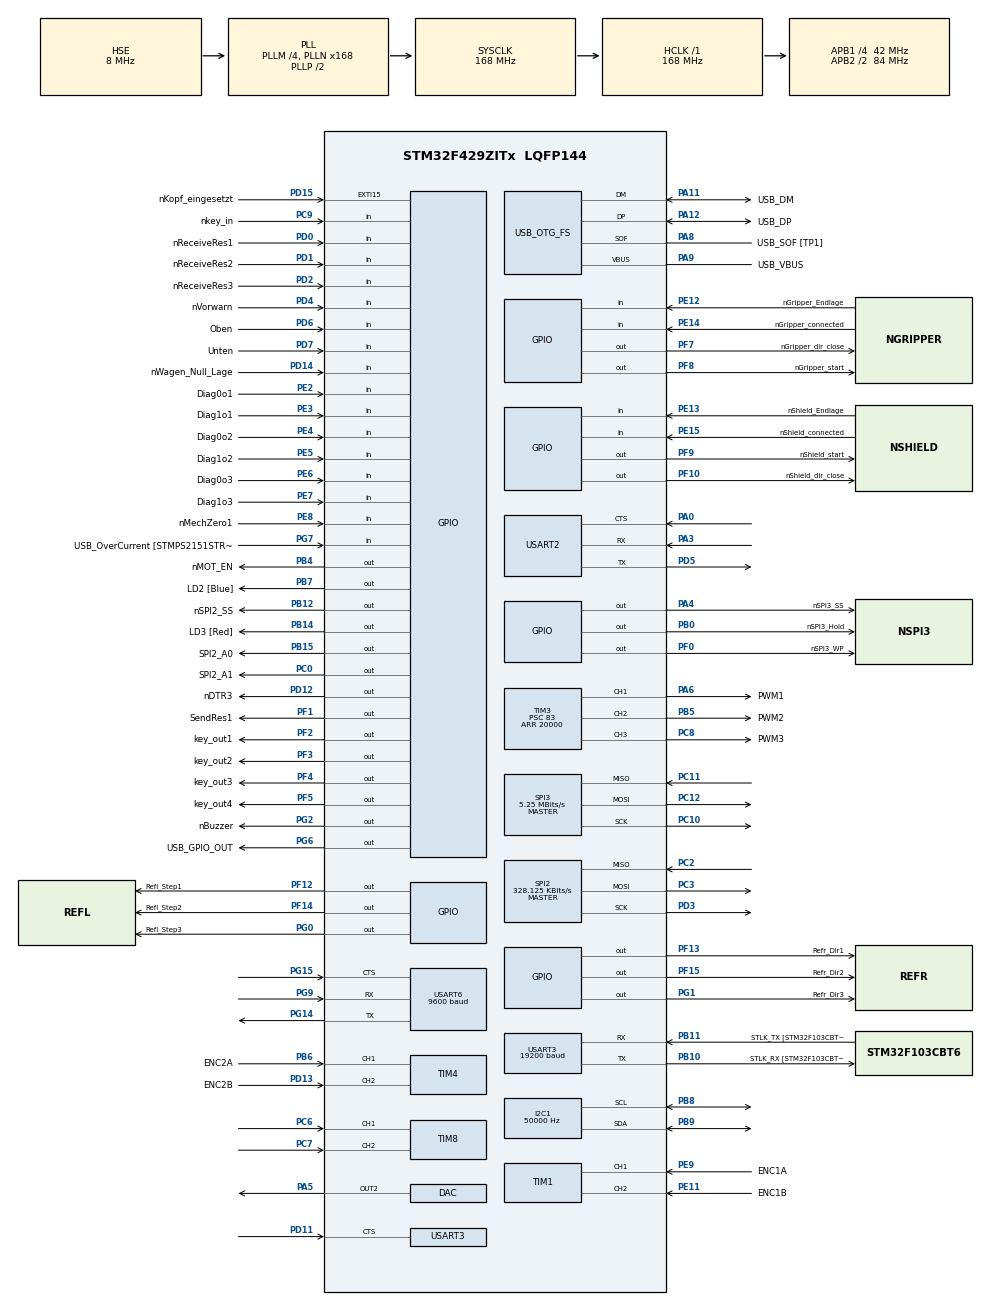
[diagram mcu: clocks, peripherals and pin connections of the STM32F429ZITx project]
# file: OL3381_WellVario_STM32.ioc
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I2C1.ClockSpeed=50000
IWDG.Prescaler=IWDG_PRESCALER_32
Mcu.Family=STM32F4
Mcu.Name=STM32F429ZITx
Mcu.Package=LQFP144
NVIC.EXTI15_10_IRQn=true\:1\:0\:true\:false\:true\:true\:true\:true
NVIC.PriorityGroup=NVIC_PRIORITYGROUP_4
NVIC.TIM1_BRK_TIM9_IRQn=true\:1\:0\:true\:false\:true\:true\:true\:true
NVIC.TIM1_CC_IRQn=true\:1\:0\:true\:false\:true\:true\:true\:true
NVIC.TIM1_TRG_COM_TIM11_IRQn=true\:1\:0\:true\:false\:true\:true\:true\:true
NVIC.TIM1_UP_TIM10_IRQn=true\:1\:0\:true\:false\:true\:true\:true\:true
NVIC.TIM3_IRQn=true\:1\:0\:true\:false\:true\:true\:true\:true
NVIC.TIM4_IRQn=true\:1\:0\:true\:false\:true\:true\:true\:true
NVIC.TIM8_BRK_TIM12_IRQn=true\:1\:0\:true\:false\:true\:true\:true\:true
NVIC.TIM8_CC_IRQn=true\:0\:0\:false\:false\:true\:true\:true\:true
NVIC.TIM8_TRG_COM_TIM14_IRQn=true\:1\:0\:true\:false\:true\:true\:true\:true
NVIC.TIM8_UP_TIM13_IRQn=true\:1\:0\:true\:false\:true\:true\:true\:true
NVIC.USART3_IRQn=true\:0\:0\:true\:false\:true\:true\:true\:true
PA0/WKUP.Mode=CTS_Only
PA0/WKUP.Signal=USART2_CTS
PA1.GPIO_Label=RMII_REF_CLK [LAN8742A-CZ-TR_REFCLK0]
PA1.Signal=ETH_REF_CLK
PA10.GPIO_Label=USB_ID
PA10.Signal=USB_OTG_FS_ID
PA11.GPIO_Label=USB_DM
PA11.Mode=Device_Only
PA11.Signal=USB_OTG_FS_DM
PA12.GPIO_Label=USB_DP
PA12.Mode=Device_Only
PA12.Signal=USB_OTG_FS_DP
PA13.GPIO_Label=TMS
PA13.Mode=Serial_Wire
PA13.Signal=SYS_JTMS-SWDIO
PA14.GPIO_Label=TCK
PA14.Mode=Serial_Wire
PA14.Signal=SYS_JTCK-SWCLK
PA2.GPIO_Label=RMII_MDIO [LAN8742A-CZ-TR_MDIO]
PA2.Signal=ETH_MDIO
PA3.Mode=Asynchronous
PA3.Signal=USART2_RX
PA4.GPIO_Label=nSPI3_SS
PA4.Signal=GPIO_Output
PA5.GPIO_Mode=GPIO_MODE_ANALOG
PA5.GPIO_PuPd=GPIO_NOPULL
PA5.Signal=COMP_DAC2_group
PA6.GPIO_Label=PWM1
PA6.Signal=S_TIM3_CH1
PA7.GPIO_Label=RMII_CRS_DV [LAN8742A-CZ-TR_CRS_DV]
PA7.Signal=ETH_CRS_DV
PA8.GPIO_Label=USB_SOF [TP1]
PA8.Mode=Activate_SOF_FS
PA8.Signal=USB_OTG_FS_SOF
PA9.GPIO_Label=USB_VBUS
PA9.Mode=Activate_VBUS
PA9.Signal=USB_OTG_FS_VBUS
PB0.GPIO_Label=nSPI3_Hold
PB0.PinState=GPIO_PIN_SET
PB0.Signal=GPIO_Output
PB10.GPIO_Label=STLK_RX [STM32F103CBT6_PA3]
PB10.Mode=Asynchronous
PB10.Signal=USART3_TX
PB11.GPIO_Label=STLK_TX [STM32F103CBT6_PA2]
PB11.Mode=Asynchronous
PB11.Signal=USART3_RX
PB12.GPIO_Label=nSPI2_SS
PB12.PinState=GPIO_PIN_SET
PB12.Signal=GPIO_Output
PB13.GPIO_Label=RMII_TXD1 [LAN8742A-CZ-TR_TXD1]
PB13.Signal=ETH_TXD1
PB14.GPIO_Label=LD3 [Red]
PB14.Signal=GPIO_Output
PB15.GPIO_Label=SPI2_A0
PB15.PinState=GPIO_PIN_SET
PB15.Signal=GPIO_Output
PB4.GPIO_Label=nMOT_EN
PB4.PinState=GPIO_PIN_SET
PB4.Signal=GPIO_Output
PB5.GPIO_Label=PWM2
PB5.Signal=S_TIM3_CH2
PB6.GPIO_Label=ENC2A
PB6.Signal=S_TIM4_CH1
PB7.GPIO_Label=LD2 [Blue]
PB7.Signal=GPIO_Output
PB8.Mode=I2C
PB8.Signal=I2C1_SCL
PB9.Mode=I2C
PB9.Signal=I2C1_SDA
PC0.GPIO_Label=SPI2_A1
PC0.PinState=GPIO_PIN_SET
PC0.Signal=GPIO_Output
PC1.GPIO_Label=RMII_MDC [LAN8742A-CZ-TR_MDC]
PC1.Signal=ETH_MDC
PC10.Mode=Full_Duplex_Master
PC10.Signal=SPI3_SCK
PC11.Mode=Full_Duplex_Master
PC11.Signal=SPI3_MISO
PC12.Mode=Full_Duplex_Master
PC12.Signal=SPI3_MOSI
PC14/OSC32_IN.Mode=LSE-External-Oscillator
PC14/OSC32_IN.Signal=RCC_OSC32_IN
PC15/OSC32_OUT.Mode=LSE-External-Oscillator
PC15/OSC32_OUT.Signal=RCC_OSC32_OUT
PC2.Mode=Full_Duplex_Master
PC2.Signal=SPI2_MISO
PC3.Mode=Full_Duplex_Master
PC3.Signal=SPI2_MOSI
PC4.GPIO_Label=RMII_RXD0 [LAN8742A-CZ-TR_RXD0]
PC4.Signal=ETH_RXD0
PC5.GPIO_Label=RMII_RXD1 [LAN8742A-CZ-TR_RXD1]
PC5.Signal=ETH_RXD1
PC6.Signal=S_TIM8_CH1
PC7.Signal=S_TIM8_CH2
PC8.GPIO_Label=PWM3
PC8.Signal=S_TIM3_CH3
PC9.GPIO_Label=nkey_in
PC9.GPIO_PuPd=GPIO_PULLUP
PC9.Signal=GPIO_Input
PD0.GPIO_Label=nReceiveRes1
PD0.Signal=GPIO_Input
PD1.GPIO_Label=nReceiveRes2
PD1.Signal=GPIO_Input
PD11.Mode=CTS_Only
PD11.Signal=USART3_CTS
PD12.GPIO_Label=nDTR3
PD12.PinState=GPIO_PIN_RESET
PD12.Signal=GPIO_Output
PD13.GPIO_Label=ENC2B
PD13.Signal=S_TIM4_CH2
PD14.GPIO_Label=nWagen_Null_Lage
PD14.Signal=GPIO_Input
PD15.GPIO_Label=nKopf_eingesetzt
PD15.GPIO_ModeDefaultEXTI=GPIO_MODE_IT_RISING_FALLING
PD15.GPIO_PuPd=GPIO_PULLUP
PD15.Signal=GPXTI15
PD2.GPIO_Label=nReceiveRes3
PD2.Signal=GPIO_Input
PD3.Mode=Full_Duplex_Master
PD3.Signal=SPI2_SCK
PD4.GPIO_Label=nVorwarn
PD4.Signal=GPIO_Input
PD5.GPIO_Speed=GPIO_SPEED_FREQ_VERY_HIGH
PD5.Mode=Asynchronous
PD5.Signal=USART2_TX
PD6.GPIO_Label=Oben
PD6.Signal=GPIO_Input
PD7.GPIO_Label=Unten
PD7.Signal=GPIO_Input
PE11.GPIO_Label=ENC1B
PE11.Signal=S_TIM1_CH2
PE12.GPIO_Label=nGripper_Endlage
PE12.Signal=GPIO_Input
PE13.GPIO_Label=nShield_Endlage
PE13.Signal=GPIO_Input
PE14.GPIO_Label=nGripper_connected
PE14.GPIO_PuPd=GPIO_PULLUP
PE14.Signal=GPIO_Input
PE15.GPIO_Label=nShield_connected
PE15.GPIO_PuPd=GPIO_PULLUP
PE15.Signal=GPIO_Input
PE2.GPIO_Label=Diag0o1
PE2.Signal=GPIO_Input
PE3.GPIO_Label=Diag1o1
PE3.Signal=GPIO_Input
PE4.GPIO_Label=Diag0o2
PE4.Signal=GPIO_Input
PE5.GPIO_Label=Diag1o2
PE5.Signal=GPIO_Input
PE6.GPIO_Label=Diag0o3
PE6.Signal=GPIO_Input
PE7.GPIO_Label=Diag1o3
PE7.Signal=GPIO_Input
PE8.GPIO_Label=nMechZero1
PE8.Signal=GPIO_Input
PE9.GPIO_Label=ENC1A
PE9.Signal=S_TIM1_CH1
PF0.GPIO_Label=nSPI3_WP
PF0.PinState=GPIO_PIN_SET
PF0.Signal=GPIO_Output
PF1.GPIO_Label=SendRes1
PF1.Signal=GPIO_Output
PF10.GPIO_Label=nShield_dir_close
PF10.PinState=GPIO_PIN_SET
PF10.Signal=GPIO_Output
PF12.GPIO_Label=Refl_Step1
PF12.Signal=GPIO_Output
PF13.GPIO_Label=Refr_Dir1
PF13.Signal=GPIO_Output
PF14.GPIO_Label=Refl_Step2
PF14.Signal=GPIO_Output
PF15.GPIO_Label=Refr_Dir2
PF15.Signal=GPIO_Output
PF2.GPIO_Label=key_out1
PF2.Signal=GPIO_Output
PF3.GPIO_Label=key_out2
PF3.Signal=GPIO_Output
PF4.GPIO_Label=key_out3
PF4.Signal=GPIO_Output
PF5.GPIO_Label=key_out4
PF5.Signal=GPIO_Output
PF7.GPIO_Label=nGripper_dir_close
PF7.PinState=GPIO_PIN_SET
PF7.Signal=GPIO_Output
PF8.GPIO_Label=nGripper_start
PF8.PinState=GPIO_PIN_SET
PF8.Signal=GPIO_Output
PF9.GPIO_Label=nShield_start
PF9.PinState=GPIO_PIN_SET
PF9.Signal=GPIO_Output
PG0.GPIO_Label=Refl_Step3
PG0.Signal=GPIO_Output
PG1.GPIO_Label=Refr_Dir3
PG1.Signal=GPIO_Output
PG11.GPIO_Label=RMII_TX_EN [LAN8742A-CZ-TR_TXEN]
PG11.Signal=ETH_TX_EN
PG13.GPIO_Label=RMII_TXD0 [LAN8742A-CZ-TR_TXD0]
PG13.Signal=ETH_TXD0
PG14.Mode=Asynchronous
PG14.Signal=USART6_TX
PG15.Mode=CTS_Only
PG15.Signal=USART6_CTS
PG2.GPIO_Label=nBuzzer
PG2.PinState=GPIO_PIN_SET
PG2.Signal=GPIO_Output
PG6.GPIO_Label=USB_GPIO_OUT
PG6.Signal=GPIO_Output
PG7.GPIO_Label=USB_OverCurrent [STMPS2151STR_FAULT]
PG7.Signal=GPIO_Input
PG9.Mode=Asynchronous
PG9.Signal=USART6_RX
PH0/OSC_IN.GPIO_Label=MCO [STM32F103CBT6_PA8]
PH0/OSC_IN.Mode=HSE-External-Oscillator
PH0/OSC_IN.Signal=RCC_OSC_IN
PH1/OSC_OUT.Mode=HSE-External-Oscillator
PH1/OSC_OUT.Signal=RCC_OSC_OUT
ProjectManager.HeapSize=0x200
ProjectManager.StackSize=0x400
ProjectManager.TargetToolchain=STM32CubeIDE
RCC.48MHZClocksFreq_Value=48000000
RCC.AHBFreq_Value=168000000
RCC.APB1CLKDivider=RCC_HCLK_DIV4
RCC.APB1Freq_Value=42000000
RCC.APB1TimFreq_Value=84000000
RCC.APB2CLKDivider=RCC_HCLK_DIV2
RCC.APB2Freq_Value=84000000
RCC.APB2TimFreq_Value=168000000
RCC.CortexFreq_Value=168000000
RCC.HCLKFreq_Value=168000000
RCC.HSE_VALUE=8000000
RCC.HSI_VALUE=16000000
RCC.PLLM=4
RCC.PLLMUL=RCC_PLL_MUL9
RCC.PLLN=168
RCC.PLLQ=7
RCC.PRESCALERUSB=RCC_USBCLKSOURCE_PLL_DIV1_5
RCC.SYSCLKFreq_VALUE=168000000
RCC.SYSCLKSource=RCC_SYSCLKSOURCE_PLLCLK
RCC.SYSCLKSourceVirtual=RCC_SYSCLKSOURCE_PLLCLK
RCC.USBFreq_Value=48000000
RCC.VCOOutputFreq_Value=336000000
SH.COMP_DAC2_group.0=DAC_OUT2,DAC_OUT2
SH.S_TIM1_CH1.0=TIM1_CH1,Encoder_Interface
SH.S_TIM1_CH2.0=TIM1_CH2,Encoder_Interface
SH.S_TIM3_CH1.0=TIM3_CH1,PWM Generation1 CH1
SH.S_TIM3_CH2.0=TIM3_CH2,PWM Generation2 CH2
SH.S_TIM3_CH3.0=TIM3_CH3,PWM Generation3 CH3
SH.S_TIM4_CH1.0=TIM4_CH1,Encoder_Interface
SH.S_TIM4_CH2.0=TIM4_CH2,Encoder_Interface
SH.S_TIM8_CH1.0=TIM8_CH1,Encoder_Interface
SH.S_TIM8_CH2.0=TIM8_CH2,Encoder_Interface
SPI2.BaudRatePrescaler=SPI_BAUDRATEPRESCALER_128
SPI2.CLKPhase=SPI_PHASE_2EDGE
SPI2.CLKPolarity=SPI_POLARITY_HIGH
SPI2.CalculateBaudRate=328.125 KBits/s
SPI2.Direction=SPI_DIRECTION_2LINES
SPI2.Mode=SPI_MODE_MASTER
SPI2.VirtualType=VM_MASTER
SPI3.BaudRatePrescaler=SPI_BAUDRATEPRESCALER_8
SPI3.CLKPhase=SPI_PHASE_2EDGE
SPI3.CLKPolarity=SPI_POLARITY_HIGH
SPI3.CalculateBaudRate=5.25 MBits/s
SPI3.Direction=SPI_DIRECTION_2LINES
SPI3.Mode=SPI_MODE_MASTER
SPI3.VirtualType=VM_MASTER
TIM1.EncoderMode=TIM_ENCODERMODE_TI12
TIM1.IC1Polarity=TIM_ICPOLARITY_FALLING
TIM1.IC2Polarity=TIM_ICPOLARITY_FALLING
TIM3.AutoReloadPreload=TIM_AUTORELOAD_PRELOAD_DISABLE
TIM3.Channel-PWM\ Generation1\ CH1=TIM_CHANNEL_1
TIM3.Channel-PWM\ Generation2\ CH2=TIM_CHANNEL_2
TIM3.Channel-PWM\ Generation3\ CH3=TIM_CHANNEL_3
TIM3.CounterMode=TIM_COUNTERMODE_UP
TIM3.OC1Preload_PWM=DISABLE
TIM3.OC2Preload_PWM=DISABLE
TIM3.OC3Preload_PWM=DISABLE
TIM3.OCFastMode_PWM-PWM\ Generation1\ CH1=TIM_OCFAST_DISABLE
TIM3.OCFastMode_PWM-PWM\ Generation2\ CH2=TIM_OCFAST_DISABLE
TIM3.OCFastMode_PWM-PWM\ Generation3\ CH3=TIM_OCFAST_DISABLE
TIM3.OCMode_PWM-PWM\ Generation2\ CH2=TIM_OCMODE_PWM1
TIM3.OCMode_PWM-PWM\ Generation3\ CH3=TIM_OCMODE_PWM1
TIM3.Period=20000
TIM3.Prescaler=83
TIM3.Pulse-PWM\ Generation1\ CH1=1000
TIM3.Pulse-PWM\ Generation2\ CH2=1500
TIM3.Pulse-PWM\ Generation3\ CH3=2000
TIM3.TIM_MasterOutputTrigger=TIM_TRGO_RESET
TIM4.EncoderMode=TIM_ENCODERMODE_TI12
TIM4.IC1Polarity=TIM_ICPOLARITY_FALLING
TIM4.IC2Polarity=TIM_ICPOLARITY_FALLING
TIM8.EncoderMode=TIM_ENCODERMODE_TI12
TIM8.IC1Polarity=TIM_ICPOLARITY_FALLING
TIM8.IC2Polarity=TIM_ICPOLARITY_FALLING
TIM8.RepetitionCounter=0
USART2.VirtualMode=VM_ASYNC
USART3.BaudRate=19200
USART3.Parity=PARITY_ODD
USART3.StopBits=STOPBITS_2
USART3.VirtualMode=VM_ASYNC
USART3.WordLength=WORDLENGTH_9B
USART6.BaudRate=9600
USART6.VirtualMode=VM_ASYNC
USB_OTG_FS.VirtualMode=Device_Only
VP_IWDG_VS_IWDG.Mode=IWDG_Activate
VP_TIM3_VS_ClockSourceINT.Mode=Internal
board=NUCLEO-F429ZI

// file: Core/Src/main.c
/* USER CODE BEGIN Header */
/**
  ******************************************************************************
  * @file           : main.c
  * @brief          : Main program body
  ******************************************************************************
  * @attention
  *
  * Copyright (c) 2022 STMicroelectronics.
  * All rights reserved.
  *
  * This software is licensed under terms that can be found in the LICENSE file
  * in the root directory of this software component.
  * If no LICENSE file comes with this software,it is provided AS-IS.
  *
  ******************************************************************************
  */
/* USER CODE END Header */
#include "main.h"

/* USER CODE BEGIN Includes */
#include <stdbool.h>							// define bool types
#include <stdio.h>								// for types in printf
#include <string.h>								// for types in printf
#include <math.h>								// für float

#include <main.h>
#include <MAIN_CYBI.h>							// ... define (old) type definitions

// ---------- BASE
#include <ig_define.h>
// ---------- Inc
#include <_encoder.h>
#include <_i2c_fram.h>
#include <_pwm_servo.h>
#include <_spi_eeprom.h>
#include <_tmc5130a.h>
#include <_uart_terminal.h>
// ---------- Master
#include <ch_ig_head.h>							// P2.8
#include <ch_ig_config.h>						// EEPROMReadDeviceType
// ---------- Pipettor_Allgemein/VolumenKorrektur
// ---------- Pipettor_Allgemein

/* USER CODE END Includes */

/* USER CODE BEGIN PTD */
const char HW_Revision[] ={"2.0"};
/* USER CODE END PTD */

DAC_HandleTypeDef hdac;

I2C_HandleTypeDef hi2c1;

IWDG_HandleTypeDef hiwdg;

SPI_HandleTypeDef hspi2;
SPI_HandleTypeDef hspi3;

TIM_HandleTypeDef htim1;
TIM_HandleTypeDef htim3;
TIM_HandleTypeDef htim4;
TIM_HandleTypeDef htim8;

UART_HandleTypeDef huart2;
UART_HandleTypeDef huart3;
UART_HandleTypeDef huart6;

PCD_HandleTypeDef hpcd_USB_OTG_FS;

/* USER CODE BEGIN PV */

uword g_uwWaitTime;
uword g_uwKeyRepeatTime;
uword g_uwBeepTime;
uword g_uwTimeout;
uword g_uwHeadSafetyTime;

//gloabl flags for polling
volatile int32_t global_flag_counter_10ms;
volatile int32_t global_counter_10ms;

bool _Diag0o1;
bool _Diag1o1;
bool _Diag0o2;
bool _Diag1o2;
bool _Diag0o3;
bool _Diag1o3;
bool _nReceiveRes1;
bool _nReceiveRes2;
bool _nReceiveRes3;
bool _nWagen_Null_Lage;
bool _nVorwarn;
bool _Oben;
bool _Unten;
bool _nKopf_eingesetzt;
bool _nMechZero1;
bool _nGripper_connected;
bool _nShield_connected;
bool _nGripper_Endlage;
bool _nShield_Endlage;

/* USER CODE END PV */

void SystemClock_Config(void);
static void MX_GPIO_Init(void);
static void MX_USART3_UART_Init(void);
static void MX_USB_OTG_FS_PCD_Init(void);
static void MX_TIM4_Init(void);
static void MX_TIM3_Init(void);
static void MX_TIM8_Init(void);
static void MX_TIM1_Init(void);
static void MX_I2C1_Init(void);
static void MX_USART2_UART_Init(void);
static void MX_USART6_UART_Init(void);
static void MX_SPI2_Init(void);
static void MX_SPI3_Init(void);
static void MX_DAC_Init(void);
static void MX_IWDG_Init(void);
/* USER CODE BEGIN PFP */

// encoder (old Timer - Register replacement)
extern volatile int16_t HrzEncoder;					// Enc.1 (was T2) replacements for old (C167CS) hardware registers
extern volatile int16_t VertEncoder;				// Enc.2 (was T3)
volatile int16_t 		T4Encoder; 					// Enc.3 (Was T4) nur bei Drehtisch (Disk) angeschlossen,initialisiert,aber nicht genutzt

// ----- tick, Timer, Watchdog
void HAL_IncTick(void)
{								// cycle: 10 ms
	uwTick += uwTickFreq;							// original system function
}

void TimeCounters10ms(void)
{
	if(g_uwTimeout > 0) g_uwTimeout--;
	if(g_uwWaitTime > 0) g_uwWaitTime--;
	if(g_uwBeepTime > 0) g_uwBeepTime--;
	if(g_uwKeyRepeatTime > 0) g_uwKeyRepeatTime--;
}

void SetWaitTime(unsigned short usValue)
{
	g_uwWaitTime = usValue;
}

unsigned short IsWaitTime(void)
{
	return g_uwWaitTime;
}

void ResetWaitTime(void)
{
	g_uwWaitTime = 0;
}

void WDO(void)
{
	HAL_IWDG_Refresh(&hiwdg);						// timeout: 4 s
}

// keyboard
void KeySetRequest(uint16_t KeyNumber)
{
	HAL_GPIO_WritePin(key_out1_GPIO_Port,key_out1_Pin,(KeyNumber & 1));
	HAL_GPIO_WritePin(key_out2_GPIO_Port,key_out2_Pin,(KeyNumber & 2));
	HAL_GPIO_WritePin(key_out3_GPIO_Port,key_out3_Pin,(KeyNumber & 4));
	HAL_GPIO_WritePin(key_out4_GPIO_Port,key_out4_Pin,(KeyNumber & 8));
}
/* USER CODE END PFP */

int main(void)
{

	/* MCU Configuration--------------------------------------------------------*/

	/* Reset of all peripherals, Initializes the Flash interface and the Systick. */
	HAL_Init();

	/* Configure the system clock */
	SystemClock_Config();

	/* Initialize all configured peripherals */
	MX_GPIO_Init();
	MX_USART3_UART_Init();
	MX_USB_OTG_FS_PCD_Init();
	MX_TIM4_Init();
	MX_TIM3_Init();
	MX_TIM8_Init();
	MX_TIM1_Init();
	MX_I2C1_Init();
	MX_USART2_UART_Init();
	MX_USART6_UART_Init();
	MX_SPI2_Init();
	MX_SPI3_Init();
	MX_DAC_Init();
	MX_IWDG_Init();

	//while(HAL_SetTickFreq(HAL_TICK_FREQ_100HZ) != HAL_OK)	WDO();	// init 10 ms Tick
	while(HAL_SetTickFreq(HAL_TICK_FREQ_1KHZ) != HAL_OK)	WDO();	// init  1 ms Tick

	// ----- keyboard
	KeySetRequest(0);		// set Decoder Address to key1

	// ----- Gripper,Shield -----
	Gripper_Stop;
	Gripper_Open;
	Shield_Stop;
	Shield_Open_VcStop;

	// ----- read io state
	for (int i=0; i<5;i++)
	{
		_Diag0o1 = Diag0o1_RD;							//Poll			(reserviert Motorsteuerung)
		_Diag1o1 = Diag1o1_RD;							//Poll		H
		_Diag0o2 = Diag0o2_RD;							//Poll
		_Diag1o2 = Diag1o2_RD;							//Poll		H
		_Diag0o3 = Diag0o3_RD;							//Poll
		_Diag1o3 = Diag1o3_RD;							//Poll		H

		_nReceiveRes1 = nReceiveRes1_RD;				//ExtI0		L	P5_0	DiskFineZero						(ENC1_N Drehtisch_485 - nur bei "Disk" aktiv)
		_nReceiveRes2 = nReceiveRes2_RD;				//ExtI1			P5_4										(ENC2_N Ausheber)
		_nReceiveRes3 = nReceiveRes3_RD;				//ExtI2			P5_8	!DiskRawZeroRequest					(ENC3_N Drehtisch_485 - nur Grobnull)

		_nVorwarn = nVorwarn_RD;						//ExtI4			IN0[1]	VertReadAdvancePos					(Ausheber)
		_Oben = Oben_RD;								//ExtI6		H	IN0[4]	unused								(Ausheber)
		_Unten = Unten_RD;								//ExtI7			IN0[0]	VertReadEndPos						(Ausheber)

		_nKopf_eingesetzt = nKopf_eingesetzt_RD;		//ExtI15	L	P2_8	pos_edge -> UnexpectedHeadRemove()	(XS19/2, mit XS6 verbunden)
		_nMechZero1 = nMechZero1_RD;					//ExtI8		L	P5_2	HeadConnectionPin; PullUp			(XS6, mit XS19/2 verbunden)

		//	nMechZero2 = HIGH;							//Closed		P5_6	IsHeadShieldOpen / JALOUSIE_OPEN	S4 - Abdeckung

		//	nMechZero3 = HIGH;							//Closed		P5_10	HrzZeroRequest3714					S2 - Kopfhaube

		_nWagen_Null_Lage = nWagen_Null_Lage_RD;		//ExtI14				HrzZeroRequestStd					(Wagen)

		//	IsHeadShieldOpen: (IN2[2]==0) (S4 Jalousie bis V1.20), (IN2[3]==0) (S4 Jalousie ab V1.21), (P5_6==0) (S4 Überwachung Abdeckung)

		_nGripper_connected = nGripper_connected_RD;	//Poll			(Parkzange)
		_nGripper_Endlage = nGripper_Endlage_RD;		//ExtI12

		_nShield_connected = nShield_connected_RD;		//Poll			(Schutzschild)
		_nShield_Endlage = nShield_Endlage_RD;			//ExtI13

		HAL_Delay(10);
		WDO();
	}

	// ----- PWM
	PWM_init();			// Stop_all,0° = 1520ms

	// ----- DAC ----- (Ain_Iref)
	HAL_DAC_Start(&hdac,DAC_CHANNEL_2);
	HAL_DAC_SetValue(&hdac,DAC_CHANNEL_2,DAC_ALIGN_12B_R,0x07FF);	// 50% = around 2V35 @ TMC,reserved / not used now

	// ----- Encoder -----
	SendRes1_H;			// no index puls
	ENCODER_start();	// start Encoder Counter
	// replacements for old (C167CS) hardware registers:
	HrzEncoder = 0;		// Enc.1 (was T2) Hrz / Tisch
	VertEncoder = 0;	// Enc.2 (was T3) Vert / Ausheber
	T4Encoder = 0; 		// Enc.3 (Was T4) Disk / Drehtisch - initialisiert, aber ungenutzt

	// ----- nucleo
	LD1_ON;				// Green (EEPROM nSPI3_Hold = not holding)
	LD2_ON;				// Blue
	LD3_ON;				// Red
	HAL_Delay(100);
	LD1_OFF;			// Green (EEPROM nSPI3_Hold)
	LD2_OFF;			// Blue
	LD3_OFF;			// Red
	WDO();

	// ----- Steppers -----
	HAL_Delay(900);	// wait of end TMC5130 Controllers boot-sequence
	WDO();

	MOT_EN_ON;
	SPI2_A0_H;			// address 4 -> dummy unit
	SPI2_A1_H;
	nSPI2_SS_H;			// not selected

	tmc5130a_init();	// Set Motor Preferences
	HAL_Delay(100);
	WDO();

	float varrpm = 0.2;												// Test mit Fließkommazahl
	tmc5130a_VELOCITY(0, (uint32_t) (varrpm	*M1_SpU	*uSpS /60));	// Pumpe
	tmc5130a_VELOCITY(1, (uint32_t) (varrpm	*M2_SpU	*uSpS /60));	// Ausheber
	tmc5130a_VELOCITY(2, (uint32_t) (varrpm	*M3_SpU	*uSpS /60));	// Drehtisch

	// ----- Buzzer -----
	Buzzer_Beep(50);

	// ----- uart -----
	DTR3_ON;
	UART3_Start();
	setvbuf(stdout, NULL, _IONBF, 0); //Send strings without nullterminator
	setvbuf( stdin, NULL, _IONBF, 0); //get single chars

	/* Infinite loop */
	while (1)
	{
		WDO();
		main_cybi();					// start / run original maschine
	}

}

void SystemClock_Config(void)
{
	RCC_OscInitTypeDef RCC_OscInitStruct = {0};
	RCC_ClkInitTypeDef RCC_ClkInitStruct = {0};

	/** Configure the main internal regulator output voltage
	*/
	__HAL_RCC_PWR_CLK_ENABLE();
	__HAL_PWR_VOLTAGESCALING_CONFIG(PWR_REGULATOR_VOLTAGE_SCALE1);

	/** Initializes the RCC Oscillators according to the specified parameters
	* in the RCC_OscInitTypeDef structure.
	*/
	RCC_OscInitStruct.OscillatorType = RCC_OSCILLATORTYPE_LSI|RCC_OSCILLATORTYPE_HSE;
	RCC_OscInitStruct.HSEState = RCC_HSE_ON;
	RCC_OscInitStruct.LSIState = RCC_LSI_ON;
	RCC_OscInitStruct.PLL.PLLState = RCC_PLL_ON;
	RCC_OscInitStruct.PLL.PLLSource = RCC_PLLSOURCE_HSE;
	RCC_OscInitStruct.PLL.PLLM = 4;
	RCC_OscInitStruct.PLL.PLLN = 168;
	RCC_OscInitStruct.PLL.PLLP = RCC_PLLP_DIV2;
	RCC_OscInitStruct.PLL.PLLQ = 7;
	if (HAL_RCC_OscConfig(&RCC_OscInitStruct) != HAL_OK)
	{
		Error_Handler();
	}

	/** Initializes the CPU, AHB and APB buses clocks
	*/
	RCC_ClkInitStruct.ClockType = RCC_CLOCKTYPE_HCLK|RCC_CLOCKTYPE_SYSCLK
							  |RCC_CLOCKTYPE_PCLK1|RCC_CLOCKTYPE_PCLK2;
	RCC_ClkInitStruct.SYSCLKSource = RCC_SYSCLKSOURCE_PLLCLK;
	RCC_ClkInitStruct.AHBCLKDivider = RCC_SYSCLK_DIV1;
	RCC_ClkInitStruct.APB1CLKDivider = RCC_HCLK_DIV4;
	RCC_ClkInitStruct.APB2CLKDivider = RCC_HCLK_DIV2;

	if (HAL_RCC_ClockConfig(&RCC_ClkInitStruct, FLASH_LATENCY_5) != HAL_OK)
	{
		Error_Handler();
	}
}

static void MX_DAC_Init(void)
{

	DAC_ChannelConfTypeDef sConfig = {0};

	/** DAC Initialization
	*/
	hdac.Instance = DAC;
	if (HAL_DAC_Init(&hdac) != HAL_OK)
	{
		Error_Handler();
	}

	/** DAC channel OUT2 config
	*/
	sConfig.DAC_Trigger = DAC_TRIGGER_NONE;
	sConfig.DAC_OutputBuffer = DAC_OUTPUTBUFFER_ENABLE;
	if (HAL_DAC_ConfigChannel(&hdac, &sConfig, DAC_CHANNEL_2) != HAL_OK)
	{
		Error_Handler();
	}
}

static void MX_I2C1_Init(void)
{

	hi2c1.Instance = I2C1;
	hi2c1.Init.ClockSpeed = 50000;
	hi2c1.Init.DutyCycle = I2C_DUTYCYCLE_2;
	hi2c1.Init.OwnAddress1 = 0;
	hi2c1.Init.AddressingMode = I2C_ADDRESSINGMODE_7BIT;
	hi2c1.Init.DualAddressMode = I2C_DUALADDRESS_DISABLE;
	hi2c1.Init.OwnAddress2 = 0;
	hi2c1.Init.GeneralCallMode = I2C_GENERALCALL_DISABLE;
	hi2c1.Init.NoStretchMode = I2C_NOSTRETCH_DISABLE;
	if (HAL_I2C_Init(&hi2c1) != HAL_OK)
	{
		Error_Handler();
	}

	/** Configure Analogue filter
	*/
	if (HAL_I2CEx_ConfigAnalogFilter(&hi2c1, I2C_ANALOGFILTER_ENABLE) != HAL_OK)
	{
		Error_Handler();
	}

	/** Configure Digital filter
	*/
	if (HAL_I2CEx_ConfigDigitalFilter(&hi2c1, 0) != HAL_OK)
	{
		Error_Handler();
	}

}

static void MX_IWDG_Init(void)
{

	hiwdg.Instance = IWDG;
	hiwdg.Init.Prescaler = IWDG_PRESCALER_32;
	hiwdg.Init.Reload = 4095;
	if (HAL_IWDG_Init(&hiwdg) != HAL_OK)
	{
		Error_Handler();
	}

}

static void MX_SPI2_Init(void)
{

	/* SPI2 parameter configuration*/
	hspi2.Instance = SPI2;
	hspi2.Init.Mode = SPI_MODE_MASTER;
	hspi2.Init.Direction = SPI_DIRECTION_2LINES;
	hspi2.Init.DataSize = SPI_DATASIZE_8BIT;
	hspi2.Init.CLKPolarity = SPI_POLARITY_HIGH;
	hspi2.Init.CLKPhase = SPI_PHASE_2EDGE;
	hspi2.Init.NSS = SPI_NSS_SOFT;
	hspi2.Init.BaudRatePrescaler = SPI_BAUDRATEPRESCALER_128;
	hspi2.Init.FirstBit = SPI_FIRSTBIT_MSB;
	hspi2.Init.TIMode = SPI_TIMODE_DISABLE;
	hspi2.Init.CRCCalculation = SPI_CRCCALCULATION_DISABLE;
	hspi2.Init.CRCPolynomial = 10;
	if (HAL_SPI_Init(&hspi2) != HAL_OK)
	{
		Error_Handler();
	}

}

static void MX_SPI3_Init(void)
{

	/* SPI3 parameter configuration*/
	hspi3.Instance = SPI3;
	hspi3.Init.Mode = SPI_MODE_MASTER;
	hspi3.Init.Direction = SPI_DIRECTION_2LINES;
	hspi3.Init.DataSize = SPI_DATASIZE_8BIT;
	hspi3.Init.CLKPolarity = SPI_POLARITY_HIGH;
	hspi3.Init.CLKPhase = SPI_PHASE_2EDGE;
	hspi3.Init.NSS = SPI_NSS_SOFT;
	hspi3.Init.BaudRatePrescaler = SPI_BAUDRATEPRESCALER_8;
	hspi3.Init.FirstBit = SPI_FIRSTBIT_MSB;
	hspi3.Init.TIMode = SPI_TIMODE_DISABLE;
	hspi3.Init.CRCCalculation = SPI_CRCCALCULATION_DISABLE;
	hspi3.Init.CRCPolynomial = 10;
	if (HAL_SPI_Init(&hspi3) != HAL_OK)
	{
		Error_Handler();
	}

}

static void MX_TIM1_Init(void)
{

	TIM_Encoder_InitTypeDef sConfig = {0};
	TIM_MasterConfigTypeDef sMasterConfig = {0};

	htim1.Instance = TIM1;
	htim1.Init.Prescaler = 0;
	htim1.Init.CounterMode = TIM_COUNTERMODE_UP;
	htim1.Init.Period = 65535;
	htim1.Init.ClockDivision = TIM_CLOCKDIVISION_DIV1;
	htim1.Init.RepetitionCounter = 0;
	htim1.Init.AutoReloadPreload = TIM_AUTORELOAD_PRELOAD_DISABLE;
	sConfig.EncoderMode = TIM_ENCODERMODE_TI12;
	sConfig.IC1Polarity = TIM_ICPOLARITY_FALLING;
	sConfig.IC1Selection = TIM_ICSELECTION_DIRECTTI;
	sConfig.IC1Prescaler = TIM_ICPSC_DIV1;
	sConfig.IC1Filter = 0;
	sConfig.IC2Polarity = TIM_ICPOLARITY_FALLING;
	sConfig.IC2Selection = TIM_ICSELECTION_DIRECTTI;
	sConfig.IC2Prescaler = TIM_ICPSC_DIV1;
	sConfig.IC2Filter = 0;
	if (HAL_TIM_Encoder_Init(&htim1, &sConfig) != HAL_OK)
	{
		Error_Handler();
	}
	sMasterConfig.MasterOutputTrigger = TIM_TRGO_RESET;
	sMasterConfig.MasterSlaveMode = TIM_MASTERSLAVEMODE_DISABLE;
	if (HAL_TIMEx_MasterConfigSynchronization(&htim1, &sMasterConfig) != HAL_OK)
	{
		Error_Handler();
	}
}

static void MX_TIM3_Init(void)
{

	TIM_ClockConfigTypeDef sClockSourceConfig = {0};
	TIM_MasterConfigTypeDef sMasterConfig = {0};
	TIM_OC_InitTypeDef sConfigOC = {0};

	htim3.Instance = TIM3;
	htim3.Init.Prescaler = 83;
	htim3.Init.CounterMode = TIM_COUNTERMODE_UP;
	htim3.Init.Period = 20000;
	htim3.Init.ClockDivision = TIM_CLOCKDIVISION_DIV1;
	htim3.Init.AutoReloadPreload = TIM_AUTORELOAD_PRELOAD_DISABLE;
	if (HAL_TIM_Base_Init(&htim3) != HAL_OK)
	{
		Error_Handler();
	}
	sClockSourceConfig.ClockSource = TIM_CLOCKSOURCE_INTERNAL;
	if (HAL_TIM_ConfigClockSource(&htim3, &sClockSourceConfig) != HAL_OK)
	{
		Error_Handler();
	}
	if (HAL_TIM_PWM_Init(&htim3) != HAL_OK)
	{
		Error_Handler();
	}
	sMasterConfig.MasterOutputTrigger = TIM_TRGO_RESET;
	sMasterConfig.MasterSlaveMode = TIM_MASTERSLAVEMODE_DISABLE;
	if (HAL_TIMEx_MasterConfigSynchronization(&htim3, &sMasterConfig) != HAL_OK)
	{
		Error_Handler();
	}
	sConfigOC.OCMode = TIM_OCMODE_PWM1;
	sConfigOC.Pulse = 1000;
	sConfigOC.OCPolarity = TIM_OCPOLARITY_HIGH;
	sConfigOC.OCFastMode = TIM_OCFAST_DISABLE;
	if (HAL_TIM_PWM_ConfigChannel(&htim3, &sConfigOC, TIM_CHANNEL_1) != HAL_OK)
	{
		Error_Handler();
	}
	__HAL_TIM_DISABLE_OCxPRELOAD(&htim3, TIM_CHANNEL_1);
	sConfigOC.Pulse = 1500;
	if (HAL_TIM_PWM_ConfigChannel(&htim3, &sConfigOC, TIM_CHANNEL_2) != HAL_OK)
	{
		Error_Handler();
	}
	__HAL_TIM_DISABLE_OCxPRELOAD(&htim3, TIM_CHANNEL_2);
	sConfigOC.Pulse = 2000;
	if (HAL_TIM_PWM_ConfigChannel(&htim3, &sConfigOC, TIM_CHANNEL_3) != HAL_OK)
	{
		Error_Handler();
	}
	__HAL_TIM_DISABLE_OCxPRELOAD(&htim3, TIM_CHANNEL_3);
	HAL_TIM_MspPostInit(&htim3);

}

static void MX_TIM4_Init(void)
{

	TIM_Encoder_InitTypeDef sConfig = {0};
	TIM_MasterConfigTypeDef sMasterConfig = {0};

	htim4.Instance = TIM4;
	htim4.Init.Prescaler = 0;
	htim4.Init.CounterMode = TIM_COUNTERMODE_UP;
	htim4.Init.Period = 65535;
	htim4.Init.ClockDivision = TIM_CLOCKDIVISION_DIV1;
	htim4.Init.AutoReloadPreload = TIM_AUTORELOAD_PRELOAD_DISABLE;
	sConfig.EncoderMode = TIM_ENCODERMODE_TI12;
	sConfig.IC1Polarity = TIM_ICPOLARITY_FALLING;
	sConfig.IC1Selection = TIM_ICSELECTION_DIRECTTI;
	sConfig.IC1Prescaler = TIM_ICPSC_DIV1;
	sConfig.IC1Filter = 0;
	sConfig.IC2Polarity = TIM_ICPOLARITY_FALLING;
	sConfig.IC2Selection = TIM_ICSELECTION_DIRECTTI;
	sConfig.IC2Prescaler = TIM_ICPSC_DIV1;
	sConfig.IC2Filter = 0;
	if (HAL_TIM_Encoder_Init(&htim4, &sConfig) != HAL_OK)
	{
		Error_Handler();
	}
	sMasterConfig.MasterOutputTrigger = TIM_TRGO_RESET;
	sMasterConfig.MasterSlaveMode = TIM_MASTERSLAVEMODE_DISABLE;
	if (HAL_TIMEx_MasterConfigSynchronization(&htim4, &sMasterConfig) != HAL_OK)
	{
		Error_Handler();
	}

}

static void MX_TIM8_Init(void)
{

	TIM_Encoder_InitTypeDef sConfig = {0};
	TIM_MasterConfigTypeDef sMasterConfig = {0};

	htim8.Instance = TIM8;
	htim8.Init.Prescaler = 0;
	htim8.Init.CounterMode = TIM_COUNTERMODE_UP;
	htim8.Init.Period = 65535;
	htim8.Init.ClockDivision = TIM_CLOCKDIVISION_DIV1;
	htim8.Init.RepetitionCounter = 0;
	htim8.Init.AutoReloadPreload = TIM_AUTORELOAD_PRELOAD_DISABLE;
	sConfig.EncoderMode = TIM_ENCODERMODE_TI12;
	sConfig.IC1Polarity = TIM_ICPOLARITY_FALLING;
	sConfig.IC1Selection = TIM_ICSELECTION_DIRECTTI;
	sConfig.IC1Prescaler = TIM_ICPSC_DIV1;
	sConfig.IC1Filter = 0;
	sConfig.IC2Polarity = TIM_ICPOLARITY_FALLING;
	sConfig.IC2Selection = TIM_ICSELECTION_DIRECTTI;
	sConfig.IC2Prescaler = TIM_ICPSC_DIV1;
	sConfig.IC2Filter = 0;
	if (HAL_TIM_Encoder_Init(&htim8, &sConfig) != HAL_OK)
	{
		Error_Handler();
	}
	sMasterConfig.MasterOutputTrigger = TIM_TRGO_RESET;
	sMasterConfig.MasterSlaveMode = TIM_MASTERSLAVEMODE_DISABLE;
	if (HAL_TIMEx_MasterConfigSynchronization(&htim8, &sMasterConfig) != HAL_OK)
	{
		Error_Handler();
	}

}

static void MX_USART2_UART_Init(void)
{

	huart2.Instance = USART2;
	huart2.Init.BaudRate = 115200;
	huart2.Init.WordLength = UART_WORDLENGTH_8B;
	huart2.Init.StopBits = UART_STOPBITS_1;
	huart2.Init.Parity = UART_PARITY_NONE;
	huart2.Init.Mode = UART_MODE_TX_RX;
	huart2.Init.HwFlowCtl = UART_HWCONTROL_CTS;
	huart2.Init.OverSampling = UART_OVERSAMPLING_16;
	if (HAL_UART_Init(&huart2) != HAL_OK)
	{
		Error_Handler();
	}

}

static void MX_USART3_UART_Init(void)
{

	huart3.Instance = USART3;
	huart3.Init.BaudRate = 19200;
	huart3.Init.WordLength = UART_WORDLENGTH_9B;
	huart3.Init.StopBits = UART_STOPBITS_2;
	huart3.Init.Parity = UART_PARITY_ODD;
	huart3.Init.Mode = UART_MODE_TX_RX;
	huart3.Init.HwFlowCtl = UART_HWCONTROL_NONE;
	huart3.Init.OverSampling = UART_OVERSAMPLING_16;
	if (HAL_UART_Init(&huart3) != HAL_OK)
	{
		Error_Handler();
	}

}

static void MX_USART6_UART_Init(void)
{

	huart6.Instance = USART6;
	huart6.Init.BaudRate = 9600;
	huart6.Init.WordLength = UART_WORDLENGTH_8B;
	huart6.Init.StopBits = UART_STOPBITS_1;
	huart6.Init.Parity = UART_PARITY_NONE;
	huart6.Init.Mode = UART_MODE_TX_RX;
	huart6.Init.HwFlowCtl = UART_HWCONTROL_NONE;
	huart6.Init.OverSampling = UART_OVERSAMPLING_16;
	if (HAL_UART_Init(&huart6) != HAL_OK)
	{
		Error_Handler();
	}

}

static void MX_USB_OTG_FS_PCD_Init(void)
{

	hpcd_USB_OTG_FS.Instance = USB_OTG_FS;
	hpcd_USB_OTG_FS.Init.dev_endpoints = 4;
	hpcd_USB_OTG_FS.Init.speed = PCD_SPEED_FULL;
	hpcd_USB_OTG_FS.Init.dma_enable = DISABLE;
	hpcd_USB_OTG_FS.Init.phy_itface = PCD_PHY_EMBEDDED;
	hpcd_USB_OTG_FS.Init.Sof_enable = ENABLE;
	hpcd_USB_OTG_FS.Init.low_power_enable = DISABLE;
	hpcd_USB_OTG_FS.Init.lpm_enable = DISABLE;
	hpcd_USB_OTG_FS.Init.vbus_sensing_enable = ENABLE;
	hpcd_USB_OTG_FS.Init.use_dedicated_ep1 = DISABLE;
	if (HAL_PCD_Init(&hpcd_USB_OTG_FS) != HAL_OK)
	{
		Error_Handler();
	}

}

static void MX_GPIO_Init(void)
{
	GPIO_InitTypeDef GPIO_InitStruct = {0};

	/* GPIO Ports Clock Enable */
	__HAL_RCC_GPIOE_CLK_ENABLE();
	__HAL_RCC_GPIOC_CLK_ENABLE();
	__HAL_RCC_GPIOF_CLK_ENABLE();
	__HAL_RCC_GPIOH_CLK_ENABLE();
	__HAL_RCC_GPIOA_CLK_ENABLE();
	__HAL_RCC_GPIOB_CLK_ENABLE();
	__HAL_RCC_GPIOG_CLK_ENABLE();
	__HAL_RCC_GPIOD_CLK_ENABLE();

	/*Configure GPIO pin Output Level */
	HAL_GPIO_WritePin(GPIOF, nSPI3_WP_Pin|nGripper_dir_close_Pin|nGripper_start_Pin|nShield_start_Pin
						  |nShield_dir_close_Pin, GPIO_PIN_SET);

	/*Configure GPIO pin Output Level */
	HAL_GPIO_WritePin(GPIOF, SendRes1_Pin|key_out1_Pin|key_out2_Pin|key_out3_Pin
						  |key_out4_Pin|Refl_Step1_Pin|Refr_Dir1_Pin|Refl_Step2_Pin
						  |Refr_Dir2_Pin, GPIO_PIN_RESET);

	/*Configure GPIO pin Output Level */
	HAL_GPIO_WritePin(SPI2_A1_GPIO_Port, SPI2_A1_Pin, GPIO_PIN_SET);

	/*Configure GPIO pin Output Level */
	HAL_GPIO_WritePin(nSPI3_SS_GPIO_Port, nSPI3_SS_Pin, GPIO_PIN_RESET);

	/*Configure GPIO pin Output Level */
	HAL_GPIO_WritePin(GPIOB, nSPI3_Hold_Pin|nSPI2_SS_Pin|SPI2_A0_Pin|nMOT_EN_Pin, GPIO_PIN_SET);

	/*Configure GPIO pin Output Level */
	HAL_GPIO_WritePin(GPIOG, Refl_Step3_Pin|Refr_Dir3_Pin|USB_GPIO_OUT_Pin, GPIO_PIN_RESET);

	/*Configure GPIO pin Output Level */
	HAL_GPIO_WritePin(GPIOB, LD3_Pin|LD2_Pin, GPIO_PIN_RESET);

	/*Configure GPIO pin Output Level */
	HAL_GPIO_WritePin(nDTR3_GPIO_Port, nDTR3_Pin, GPIO_PIN_RESET);

	/*Configure GPIO pin Output Level */
	HAL_GPIO_WritePin(nBuzzer_GPIO_Port, nBuzzer_Pin, GPIO_PIN_SET);

	/*Configure GPIO pins : Diag0o1_Pin Diag1o1_Pin Diag0o2_Pin Diag1o2_Pin
						   Diag0o3_Pin Diag1o3_Pin nMechZero1_Pin nGripper_Endlage_Pin
						   nShield_Endlage_Pin */
	GPIO_InitStruct.Pin = Diag0o1_Pin|Diag1o1_Pin|Diag0o2_Pin|Diag1o2_Pin
						  |Diag0o3_Pin|Diag1o3_Pin|nMechZero1_Pin|nGripper_Endlage_Pin
						  |nShield_Endlage_Pin;
	GPIO_InitStruct.Mode = GPIO_MODE_INPUT;
	GPIO_InitStruct.Pull = GPIO_NOPULL;
	HAL_GPIO_Init(GPIOE, &GPIO_InitStruct);

	/*Configure GPIO pins : nSPI3_WP_Pin SendRes1_Pin key_out1_Pin key_out2_Pin
						   key_out3_Pin key_out4_Pin nGripper_dir_close_Pin nGripper_start_Pin
						   nShield_start_Pin nShield_dir_close_Pin Refl_Step1_Pin Refr_Dir1_Pin
						   Refl_Step2_Pin Refr_Dir2_Pin */
	GPIO_InitStruct.Pin = nSPI3_WP_Pin|SendRes1_Pin|key_out1_Pin|key_out2_Pin
						  |key_out3_Pin|key_out4_Pin|nGripper_dir_close_Pin|nGripper_start_Pin
						  |nShield_start_Pin|nShield_dir_close_Pin|Refl_Step1_Pin|Refr_Dir1_Pin
						  |Refl_Step2_Pin|Refr_Dir2_Pin;
	GPIO_InitStruct.Mode = GPIO_MODE_OUTPUT_PP;
	GPIO_InitStruct.Pull = GPIO_NOPULL;
	GPIO_InitStruct.Speed = GPIO_SPEED_FREQ_LOW;
	HAL_GPIO_Init(GPIOF, &GPIO_InitStruct);

	/*Configure GPIO pin : SPI2_A1_Pin */
	GPIO_InitStruct.Pin = SPI2_A1_Pin;
	GPIO_InitStruct.Mode = GPIO_MODE_OUTPUT_PP;
	GPIO_InitStruct.Pull = GPIO_NOPULL;
	GPIO_InitStruct.Speed = GPIO_SPEED_FREQ_LOW;
	HAL_GPIO_Init(SPI2_A1_GPIO_Port, &GPIO_InitStruct);

	/*Configure GPIO pins : RMII_MDC_Pin RMII_RXD0_Pin RMII_RXD1_Pin */
	GPIO_InitStruct.Pin = RMII_MDC_Pin|RMII_RXD0_Pin|RMII_RXD1_Pin;
	GPIO_InitStruct.Mode = GPIO_MODE_AF_PP;
	GPIO_InitStruct.Pull = GPIO_NOPULL;
	GPIO_InitStruct.Speed = GPIO_SPEED_FREQ_VERY_HIGH;
	GPIO_InitStruct.Alternate = GPIO_AF11_ETH;
	HAL_GPIO_Init(GPIOC, &GPIO_InitStruct);

	/*Configure GPIO pins : RMII_REF_CLK_Pin RMII_MDIO_Pin RMII_CRS_DV_Pin */
	GPIO_InitStruct.Pin = RMII_REF_CLK_Pin|RMII_MDIO_Pin|RMII_CRS_DV_Pin;
	GPIO_InitStruct.Mode = GPIO_MODE_AF_PP;
	GPIO_InitStruct.Pull = GPIO_NOPULL;
	GPIO_InitStruct.Speed = GPIO_SPEED_FREQ_VERY_HIGH;
	GPIO_InitStruct.Alternate = GPIO_AF11_ETH;
	HAL_GPIO_Init(GPIOA, &GPIO_InitStruct);

	/*Configure GPIO pin : nSPI3_SS_Pin */
	GPIO_InitStruct.Pin = nSPI3_SS_Pin;
	GPIO_InitStruct.Mode = GPIO_MODE_OUTPUT_PP;
	GPIO_InitStruct.Pull = GPIO_NOPULL;
	GPIO_InitStruct.Speed = GPIO_SPEED_FREQ_LOW;
	HAL_GPIO_Init(nSPI3_SS_GPIO_Port, &GPIO_InitStruct);

	/*Configure GPIO pins : nSPI3_Hold_Pin nSPI2_SS_Pin LD3_Pin SPI2_A0_Pin
						   nMOT_EN_Pin LD2_Pin */
	GPIO_InitStruct.Pin = nSPI3_Hold_Pin|nSPI2_SS_Pin|LD3_Pin|SPI2_A0_Pin
						  |nMOT_EN_Pin|LD2_Pin;
	GPIO_InitStruct.Mode = GPIO_MODE_OUTPUT_PP;
	GPIO_InitStruct.Pull = GPIO_NOPULL;
	GPIO_InitStruct.Speed = GPIO_SPEED_FREQ_LOW;
	HAL_GPIO_Init(GPIOB, &GPIO_InitStruct);

	/*Configure GPIO pins : Refl_Step3_Pin Refr_Dir3_Pin nBuzzer_Pin USB_GPIO_OUT_Pin */
	GPIO_InitStruct.Pin = Refl_Step3_Pin|Refr_Dir3_Pin|nBuzzer_Pin|USB_GPIO_OUT_Pin;
	GPIO_InitStruct.Mode = GPIO_MODE_OUTPUT_PP;
	GPIO_InitStruct.Pull = GPIO_NOPULL;
	GPIO_InitStruct.Speed = GPIO_SPEED_FREQ_LOW;
	HAL_GPIO_Init(GPIOG, &GPIO_InitStruct);

	/*Configure GPIO pins : nGripper_connected_Pin nShield_connected_Pin */
	GPIO_InitStruct.Pin = nGripper_connected_Pin|nShield_connected_Pin;
	GPIO_InitStruct.Mode = GPIO_MODE_INPUT;
	GPIO_InitStruct.Pull = GPIO_PULLUP;
	HAL_GPIO_Init(GPIOE, &GPIO_InitStruct);

	/*Configure GPIO pin : RMII_TXD1_Pin */
	GPIO_InitStruct.Pin = RMII_TXD1_Pin;
	GPIO_InitStruct.Mode = GPIO_MODE_AF_PP;
	GPIO_InitStruct.Pull = GPIO_NOPULL;
	GPIO_InitStruct.Speed = GPIO_SPEED_FREQ_VERY_HIGH;
	GPIO_InitStruct.Alternate = GPIO_AF11_ETH;
	HAL_GPIO_Init(RMII_TXD1_GPIO_Port, &GPIO_InitStruct);

	/*Configure GPIO pin : nDTR3_Pin */
	GPIO_InitStruct.Pin = nDTR3_Pin;
	GPIO_InitStruct.Mode = GPIO_MODE_OUTPUT_PP;
	GPIO_InitStruct.Pull = GPIO_NOPULL;
	GPIO_InitStruct.Speed = GPIO_SPEED_FREQ_LOW;
	HAL_GPIO_Init(nDTR3_GPIO_Port, &GPIO_InitStruct);

	/*Configure GPIO pins : nWagen_Null_Lage_Pin nReceiveRes1_Pin nReceiveRes2_Pin nReceiveRes3_Pin
						   nVorwarn_Pin Oben_Pin Unten_Pin */
	GPIO_InitStruct.Pin = nWagen_Null_Lage_Pin|nReceiveRes1_Pin|nReceiveRes2_Pin|nReceiveRes3_Pin
						  |nVorwarn_Pin|Oben_Pin|Unten_Pin;
	GPIO_InitStruct.Mode = GPIO_MODE_INPUT;
	GPIO_InitStruct.Pull = GPIO_NOPULL;
	HAL_GPIO_Init(GPIOD, &GPIO_InitStruct);

	/*Configure GPIO pin : nKopf_eingesetzt_Pin */
	GPIO_InitStruct.Pin = nKopf_eingesetzt_Pin;
	GPIO_InitStruct.Mode = GPIO_MODE_IT_RISING_FALLING;
	GPIO_InitStruct.Pull = GPIO_PULLUP;
	HAL_GPIO_Init(nKopf_eingesetzt_GPIO_Port, &GPIO_InitStruct);

	/*Configure GPIO pin : USB_OverCurrent_Pin */
	GPIO_InitStruct.Pin = USB_OverCurrent_Pin;
	GPIO_InitStruct.Mode = GPIO_MODE_INPUT;
	GPIO_InitStruct.Pull = GPIO_NOPULL;
	HAL_GPIO_Init(USB_OverCurrent_GPIO_Port, &GPIO_InitStruct);

	/*Configure GPIO pin : nkey_in_Pin */
	GPIO_InitStruct.Pin = nkey_in_Pin;
	GPIO_InitStruct.Mode = GPIO_MODE_INPUT;
	GPIO_InitStruct.Pull = GPIO_PULLUP;
	HAL_GPIO_Init(nkey_in_GPIO_Port, &GPIO_InitStruct);

	/*Configure GPIO pins : RMII_TX_EN_Pin RMII_TXD0_Pin */
	GPIO_InitStruct.Pin = RMII_TX_EN_Pin|RMII_TXD0_Pin;
	GPIO_InitStruct.Mode = GPIO_MODE_AF_PP;
	GPIO_InitStruct.Pull = GPIO_NOPULL;
	GPIO_InitStruct.Speed = GPIO_SPEED_FREQ_VERY_HIGH;
	GPIO_InitStruct.Alternate = GPIO_AF11_ETH;
	HAL_GPIO_Init(GPIOG, &GPIO_InitStruct);

	/* EXTI interrupt init*/
	HAL_NVIC_SetPriority(EXTI15_10_IRQn, 1, 0);
	HAL_NVIC_EnableIRQ(EXTI15_10_IRQn);

}

/* USER CODE BEGIN 4 */
// ----- Input (Interrupts) -----
void HAL_GPIO_EXTI_Callback(uint16_t GPIO_Pin)
{
	switch(GPIO_Pin){
#ifdef nReceiveRes1_EXTI_IRQn
	case nReceiveRes1_Pin:		// EXTI0_IRQn
		_nReceiveRes1 = nReceiveRes1_RD;
		break;
#endif
#ifdef nReceiveRes2_EXTI_IRQn
	case nReceiveRes2_Pin: 		// EXTI1_IRQn
		_nReceiveRes2 = nReceiveRes2_RD;
		break;
#endif
#ifdef nReceiveRes3_EXTI_IRQn
	case nReceiveRes3_Pin:		// EXTI2_IRQn
		_nReceiveRes3 = nReceiveRes3_RD;
		break;
#endif
#ifdef Diag0o1_EXTI_IRQn
	case Diag0o1_Pin:			// EXTI2_IRQn
		_Diag0o1 = Diag0o1_RD;
		break;
#endif
#ifdef Diag1o1_EXTI_IRQn
	case Diag1o1_Pin:			// EXTI3_IRQn
		_Diag1o1 = Diag1o1_RD;
		break;
#endif
#ifdef nVorwarn_EXTI_IRQn
	case nVorwarn_Pin:			// EXTI4_IRQn
		_nVorwarn = nVorwarn_RD;
		break;
#endif
#ifdef Diag0o2_EXTI_IRQn
	case Diag0o2_Pin:			// EXTI4_IRQn
		_Diag0o2 = Diag0o2_RD;
		break;
#endif
#ifdef Diag1o2_EXTI_IRQn
	case Diag1o2_Pin:			// EXTI9_5_IRQn
		_Diag1o2 = Diag1o2_RD;
		break;
#endif
#ifdef Oben_EXTI_IRQn
	case Oben_Pin:				// EXTI9_5_IRQn (6)
		_Oben = Oben_RD;
		break;
#endif
#ifdef Unten_EXTI_IRQn
	case Unten_Pin:				// EXTI9_5_IRQn (7)
		_Unten = Unten_RD;
		break;
#endif
#ifdef nMechZero1_EXTI_IRQn
	case nMechZero1_Pin:			// EXTI9_5_IRQn (8)
		_nMechZero1 = nMechZero1_RD;
		break;
#endif
#ifdef Diag0o3_EXTI_IRQn
	case Diag0o3_Pin:			// EXTI9_5_IRQn
		_Diag0o3 = Diag0o3_RD;
		break;
#endif
#ifdef Diag1o3_EXTI_IRQn
	case Diag1o3_Pin:			// EXTI9_5_IRQn
		_Diag1o3 = Diag1o3_RD;
		break;
#endif
#ifdef nGripper_Endlage_EXTI_IRQn
	case nGripper_Endlage_Pin:	// EXTI15_10_IRQn (12)
		_nGripper_Endlage = nGripper_Endlage_RD;
		break;
#endif
#ifdef nShield_Endlage_EXTI_IRQn
	case nShield_Endlage_Pin:	// EXTI15_10_IRQn (13)
		_nShield_Endlage = nShield_Endlage_RD;
		break;
#endif
#ifdef nGripper_connected_EXTI_IRQn
	case nGripper_connected_Pin:	// EXTI15_10_IRQn
		_nGripper_connected = nGripper_connected_RD;
		break;
#endif
#ifdef nShield_connected_EXTI_IRQn
	case nShield_connected_Pin:	// EXTI15_10_IRQn
		_nShield_connected = nShield_connected_RD;
		break;
#endif
#ifdef nWagen_Null_Lage_EXTI_IRQn
	case nWagen_Null_Lage_Pin:	// EXTI15_10_IRQn (14)
		_nWagen_Null_Lage = nWagen_Null_Lage_RD;
		break;
#endif
#ifdef nKopf_eingesetzt_EXTI_IRQn
	case nKopf_eingesetzt_Pin:	// EXTI15_10_IRQn (15)
		//_nKopf_eingesetzt = nKopf_eingesetzt_RD;
		// was P2.8 -> CC8INT
//		if(_nKopf_eingesetzt){							// only positive edge
			if (HeadInterruptEnabled)
			{
				Wait(10);
				_nKopf_eingesetzt= nKopf_eingesetzt_RD;	//Störungen filtern
				if(_nKopf_eingesetzt){UnexpectedHeadRemove();}
			}
//		}
		break;
#endif
	default:
		break;
	}
}
/* USER CODE END 4 */

void Error_Handler(void)
{
	__disable_irq();
	while (1)
	{
	}
}
